# RL6842_IP_SVD register map
Vendor: Realtek
Registers are 32-bit, read-write, reset 0x0 unless marked. A register's access mark holds for its fields unless they carry their own. Offsets are from the block's base; [hi:lo] are bit positions; lines under a group give offsets from that group; {n}, {i} and the like mark numbered series.

## lp_aon
Base 0x4100C000
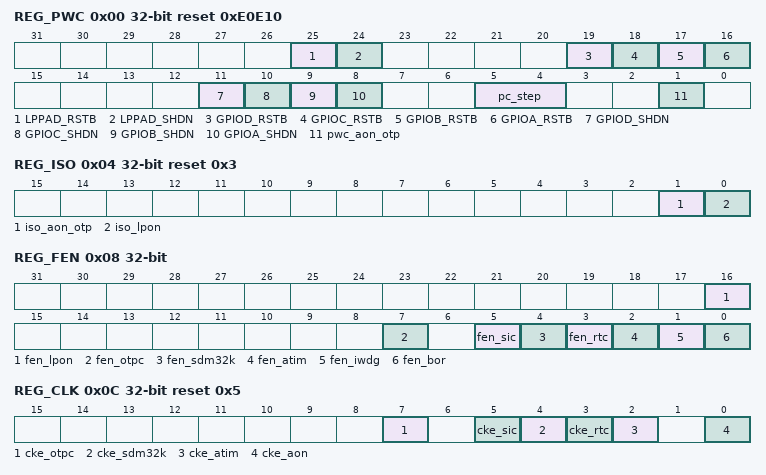
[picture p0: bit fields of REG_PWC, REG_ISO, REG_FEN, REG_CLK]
0x00 REG_PWC reset 0xE0E10
  [25] LPPAD_RSTB — 1: Release LP PAD RSTB33 (except GPIOA) 0: Global Assert LP PAD RSTB33
  [24] LPPAD_SHDN — 1: Global Enable LP PAD (except GPIOA) 0: Shutdown LP PAD Note: Default value must be fixed after AON PMC done.
  [19] GPIOD_RSTB — 1: Enable GPIOD group pad 0: Reset PAD
  [18] GPIOC_RSTB — 1: Enable GPIOC group pad 0: Reset PAD
  [17] GPIOB_RSTB — 1: Enable GPIOB group pad 0: Reset PAD
  [16] GPIOA_RSTB — 1: Enable GPIOA group pad 0: Reset PAD
  [11] GPIOD_SHDN — 1: Enable GPIOD group pad 0: Shutdown PAD
  [10] GPIOC_SHDN — 1: Enable GPIOC group pad 0: Shutdown PAD
  [9] GPIOB_SHDN — 1: Enable GPIOB group pad 0: Shutdown PAD
  [8] GPIOA_SHDN — 1: Enable GPIOA group pad 0: Shutdown PAD
  [5:4] pc_step — power cut enable time step. 0: not valid 1: 10us 2: 20us 3: 30us
  [1] pwc_aon_otp — OTP power cut enable for core power, high active. 1:enable 0:disable
0x04 REG_ISO reset 0x3
  [1] iso_aon_otp — 1: ISO signals from otp core power domain 0: Release
  [0] iso_lpon — When LDO core power on, PD_LPON is on. 1: ISO signal of LPON power domain 0: Release
0x08 REG_FEN
  [16] fen_lpon — LS global reset 1: Enable LS function 0: Disable
  [7] fen_otpc — 1: Enable OTP function 0: Disable
  [5] fen_sic — 1: enable SIC function 0: reset
  [4] fen_sdm32k — 1: Enable 32.768K SDM function 0: Disable
  [3] fen_rtc — 1: Enable RTC function 0: Disable
  [2] fen_atim — 1: Enable AON timer 0: Reset AON timer Note: AON timer starts to run only when event happens.
  [1] fen_iwdg — 1: Enable IWDG by HW autoload. Once enabled, IWDG can't be disabled unless por asserts.
  [0] fen_bor — Enable bor reset function, default is 0 when power on
0x0C REG_CLK reset 0x5
  [7] cke_otpc — 1: Enable OTPC clock 0: Disable
  [5] cke_sic — 1: Enable SIC clock 0: Disable
  [4] cke_sdm32k — 1: Enable 32.768K SDM module's clock 0: Disable
  [3] cke_rtc — 1: Enable RTC clock 0: Disable
  [2] cke_atim — 1: Enable AON timer clock 0: Disable
  [0] cke_aon — if 0, AON clock will be gated except PMC and this register. Note: AON clock can't be shutdown as analog need.
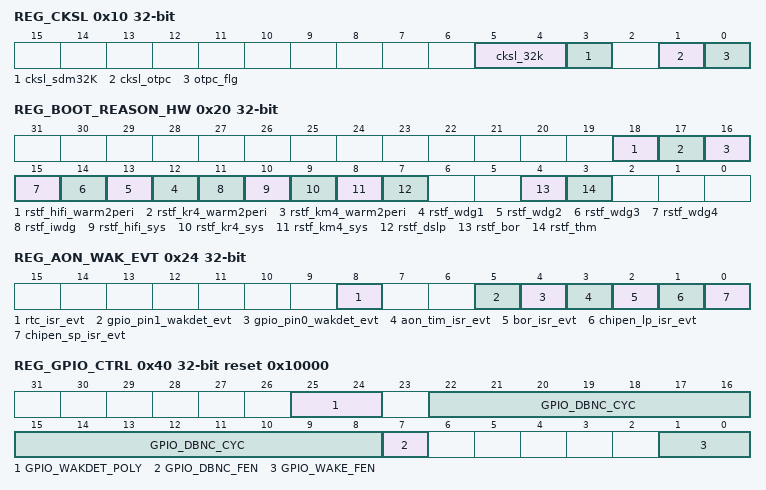
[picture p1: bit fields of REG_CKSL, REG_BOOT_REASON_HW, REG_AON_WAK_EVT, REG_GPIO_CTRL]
0x10 REG_CKSL
  [5:4] cksl_32k — This field is used to select 32K clock. 00/01: SDM32K 10: Crystal 32K 11: External 32K
  [3] cksl_sdm32K — sdm 128 clock select , this must be fixed after initial selection. 0:osc128 1:xtal lps 312.5K
  [1] cksl_otpc — This field is used to select OTPC clk 0: OSC4M 1: XLAL
  [0] otpc_flg — This field is used to indicate OTP autoload field 1: ls 0:aon
0x20 REG_BOOT_REASON_HW ro
  [18] rstf_hifi_warm2peri — This bit will be set to 1 when hifi warm resets the system. Write 1 to clear.
  [17] rstf_kr4_warm2peri — This bit will be set to 1 when kr4 warm resets the system. Write 1 to clear.
  [16] rstf_km4_warm2peri — This bit will be set to 1 when km4 warm resets the system. Write 1 to clear.
  [n+11] rstf_wdg{n} (n=1..4) — This bit will be set to 1 when WDG resets the system. Write 1 to clear.
  [11] rstf_iwdg — This bit will be set to 1 when WDG resets the system. Write 1 to clear.
  [10] rstf_hifi_sys — This bit will be set to 1 when HIFI resets the system. Write 1 to clear.
  [9] rstf_kr4_sys — This bit will be set to 1 when KR4 resets the system. Write 1 to clear.
  [8] rstf_km4_sys — This bit will be set to 1 when KM4 resets the system. Write 1 to clear.
  [7] rstf_dslp — This is boot reason for dslp exit, clear by SW write to 1.
  [4] rstf_bor — This bit will be set to 1 when BOR resets the system. Write 1 to clear.
  [3] rstf_thm — This bit will be set to 1 when THERMAL resets the system. Write 1 to clear.
0x24 REG_AON_WAK_EVT ro
  [8] rtc_isr_evt — RTC interrupt wake event occurs.
  [5] gpio_pin1_wakdet_evt — Wake event for wake pin1 1: wake event detected 0: no wake event Note: aon gpio only used to wake hw pmc, to interrupt SW, it must enable GPIO interrupt in LP GPIO IP, and the poly must be same as AON GPIO setting.
  [4] gpio_pin0_wakdet_evt — Wake event for wake pin0 1: wake event detected 0: no wake event Note: aon gpio only used to wake hw pmc, to interrupt SW, it must enable GPIO interrupt in LP GPIO IP, and the poly must be same as AON GPIO setting.
  [3] aon_tim_isr_evt — AON timer interrupt event occurs.
  [2] bor_isr_evt — bor interrupt event occurs.
  [1] chipen_lp_isr_evt — Chipen long press interrupt event occurs.
  [0] chipen_sp_isr_evt — Chipen short press interrupt event occurs.
0x30 REG_TIM_CNT ro
  [31:0] aon_tim_cnt_cur — Aon timer current count value.
0x34 REG_TIM_SET
  [31:0] aon_tim_cnt_set — Set aon time a countdown value, when timer count down, it will trigger a aon_tim event.
0x38 REG_TIM_IER
  [0] AON_TIM_IE — Timer interrupt enable 0:disable 1:enable
0x3C REG_TIM_ISR ro
  [0] AON_TIM_ISR — Timer interrupt status 0:no interrupt 1:interrupt occurs
0x40 REG_GPIO_CTRL reset 0x10000
  [25:24] GPIO_WAKDET_POLY — Wake pin polarity 0: low active 1: high active bit1: wake pin1 polarity bit0: wake pin0 polarity Note: once a wake pin is set, the pads PU/PD will be force by this poly value, and soft config have no use.
  [22:8] GPIO_DBNC_CYC — The GPIO signal will be filtered by the number of debounce cycles of specified in this register. (100k/128k)
  [7] GPIO_DBNC_FEN — 1: Enable gpio debouncer function 0: Disable Default disable for simualtion issue
  [1:0] GPIO_WAKE_FEN — 1: Enable wake pin function 0: Disable Every GPIO has its own enable. When aon pmc is not in DSLP, wake pins will not effect PMC state althrougth this bit is set.
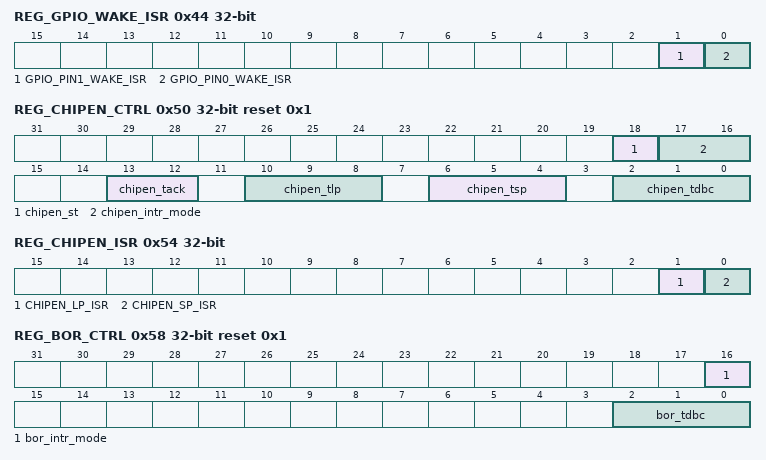
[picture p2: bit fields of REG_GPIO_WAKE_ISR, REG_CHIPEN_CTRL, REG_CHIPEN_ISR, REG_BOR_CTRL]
0x44 REG_GPIO_WAKE_ISR ro
  [1] GPIO_PIN1_WAKE_ISR — Wake pin1 interrupt status 0:no interrupt 1:interrupt occurs
  [0] GPIO_PIN0_WAKE_ISR — Wake pin0 interrupt status 0:no interrupt 1:interrupt occurs
0x50 REG_CHIPEN_CTRL access per field reset 0x1
  [18] chipen_st ro — CHIP_EN pin status 0: logic '0' on CHIP_EN pin 1: logic '1' on CHIP_EN pin
  [17:16] chipen_intr_mode rw — Chipen operation mode. 00: reset mode. When chipen pad low, hw will reset all chip 01: interrup mode. It will enable short/long press function. 1X: pulse reset mode. The transation from other value to 2'd2 will gen a posedge to set RST_PULSE_EN in HV domain. Once in pulse reset mode , this field can't be modified again , and always read out 2'b11
  [13:12] chipen_tack rw — 00: 50ms 01: 100ms 10: 200ms 11: 400ms
  [10:8] chipen_tlp rw — 000: 1000ms 001: 1500ms 010: 2000ms 011: 2500ms 100: 3000ms 101: 3500ms 110: 4000ms 111: 4500ms
  [6:4] chipen_tsp rw — 000: 0ms 001: 50ms 010: 100ms 011: 150ms 100: 200ms 101: 250ms 110: 300ms 111: 350ms
  [2:0] chipen_tdbc rw — 000: 0us 001: 100us 010: 500us 011: 1000us 100: 2000us 101: 4000us 110: 8000us 111: 16000us
0x54 REG_CHIPEN_ISR ro
  [1] CHIPEN_LP_ISR — chipen long press interrupt status 0:no interrupt 1:interrupt occurs
  [0] CHIPEN_SP_ISR — chipen short press interrupt status 0:no interrupt 1:interrupt occurs
0x58 REG_BOR_CTRL reset 0x1
  [16] bor_intr_mode — BOR operation mode. 0: reset mode. When analog detect bor, hw will trigger a bor reset. 1: interrup mode. It will raise an interrup first. If this bit set to 0, then trigger a bor reset.
  [2:0] bor_tdbc — 000: 0us 001: 100us 010: 500us 011: 1000us 100: 2000us 101: 4000us 110: 8000us 111: 16000us
0x5C REG_BOR_ISR ro
  [0] BOR_ISR — BOR interrupt status 0:no interrupt 1:interrupt occurs
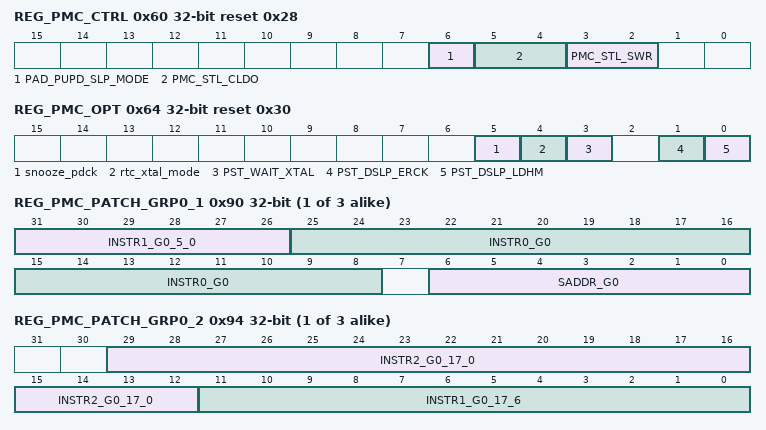
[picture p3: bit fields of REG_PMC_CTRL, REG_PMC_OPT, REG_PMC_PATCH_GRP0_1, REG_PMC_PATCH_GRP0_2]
0x60 REG_PMC_CTRL reset 0x28
  [6] PAD_PUPD_SLP_MODE — Pad pu/pd param selection 1: HW select pu/pd slp param for PAD 0: HW select pu/pd active param for PAD HW will auto-set this bit when enter or exit DSLP , SW can set for debug also .
  [5:4] PMC_STL_CLDO — wait time for core LDO stable 0: 8*T (T = 10us) 1: 16*T 2: 32*T 3: 64*T
  [3:2] PMC_STL_SWR — wait time for SWR stable 0: 64*T (T = 10us) 1: 128*T 2: 256*T 3: 512*T
0x64 REG_PMC_OPT reset 0x30
  [5] snooze_pdck — Select xtal auto pdck function for sdm calibration use xtal lps mode 1:Enable 0:Disable
  [4] rtc_xtal_mode — Select xtal mode when xtal used for sdm calibration. 1: Normal 0: LPS
  [3] PST_WAIT_XTAL — 1: When POF , polling xtal invalid signal and then run forward 0: not polling xtal invalid
  [1] PST_DSLP_ERCK — 1: Enable 100K clock for AON register access when PMC enter deep-sleep mode 0: Disable
  [0] PST_DSLP_LDHM — 0: Enable AON LDO enter into sleep mode when PMC enter deep-sleep mode 1: Disable
0x80 REG_BOOT_CFG
  [0] DSLP_RETENTION_RAM_PATCH — Deepsleep retention RAM patch
0x84 REG_RSVD_FOR_SW1
  [31:0] dummy
{0x90+8i} REG_PMC_PATCH_GRP{i}_1 (i=0..2)
  [31:26] INSTR1_G{i}_5_0 — Instruction1 of AON PMC patch group{i}
  [25:8] INSTR0_G{i} — Instruction0 of AON PMC patch group{i}
  [6:0] SADDR_G{i} — Start address of the first instruction of AON PMC patch group{i}
{0x94+8i} REG_PMC_PATCH_GRP{i}_2 (i=0..2)
  [29:12] INSTR2_G{i}_17_0 — Instruction2 of AON PMC patch group{i}
  [11:0] INSTR1_G{i}_17_6 — Instruction1 of AON PMC patch group{i}
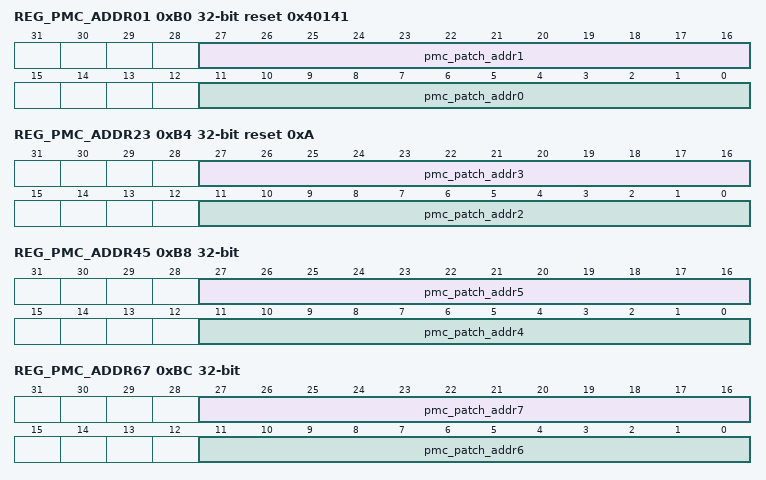
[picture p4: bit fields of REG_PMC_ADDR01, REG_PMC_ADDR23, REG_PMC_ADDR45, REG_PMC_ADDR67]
0xB0 REG_PMC_ADDR01 reset 0x40141
  [27:16] pmc_patch_addr1 — Have used for LPON patch
  [11:0] pmc_patch_addr0 — Have used for LPON patch
0xB4 REG_PMC_ADDR23 reset 0xA
  [27:16] pmc_patch_addr3 — HW used only , these are for pmc patch
  [11:0] pmc_patch_addr2 — Have used for LPON patch
0xB8 REG_PMC_ADDR45
  [27:16] pmc_patch_addr5 — HW used only , these are for pmc patch
  [11:0] pmc_patch_addr4 — HW used only , these are for pmc patch
0xBC REG_PMC_ADDR67
  [27:16] pmc_patch_addr7 — HW used only , these are for pmc patch
  [11:0] pmc_patch_addr6 — HW used only , these are for pmc patch
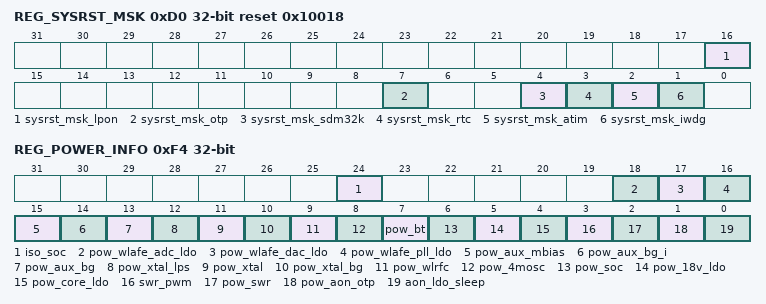
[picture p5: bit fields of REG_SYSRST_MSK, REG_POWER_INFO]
0xD0 REG_SYSRST_MSK reset 0x10018
  [16] sysrst_msk_lpon — LS global reset 1: mask LS reset when sys reset happen 0: reset by sys reset
  [7] sysrst_msk_otp — 1: mask OTP reset when sys reset happen 0: reset by sys reset
  [4] sysrst_msk_sdm32k — 1: mask 32.768K SDM reset when sys reset happen 0: reset by sys reset
  [3] sysrst_msk_rtc — 1: mask RTC reset when sys reset happen 0: reset by sys reset
  [2] sysrst_msk_atim — 1: mask AON timer 0: reset by sys reset OR warm reset Note: AON timer starts to run only when event happens.
  [1] sysrst_msk_iwdg — 1: mask AON IWDG reset 0: reset by sys reset OR warm reset
{0xE0+4i} REG_AON_BACKUP{i} (i=0..3)
  [31:0] dummy
0xF0 REG_BOUNDARY_CHK reset 0xBDC00512
  [31:0] dummy — HW used only . Used for access boundary check, AON is 256B which is 000-FF
0xF4 REG_POWER_INFO ro
  [24] iso_soc — iso control of HSOC power domain
  [18] pow_wlafe_adc_ldo — 1:Power on WLAFE adc ldo 0:Power off WLAFE adc ldo
  [17] pow_wlafe_dac_ldo — 1:Power on WLAFE dac ldo 0:Power off WLAFE dac ldo
  [16] pow_wlafe_pll_ldo — 1:Power on WLAFE power cut and pll ldo 0:Power off WLAFE power cut and pll ldo
  [15] pow_aux_mbias — 1:power on AUX BG mbias 0:power off AUX BG mbias
  [14] pow_aux_bg_i — 1:power on AUX BG current 0:power off AUX BG current
  [13] pow_aux_bg — 1:power on AUX BG 0:power off AUX BG
  [12] pow_xtal_lps — 1: Enable XTAL LPS 0: Disable XTAL LPS
  [11] pow_xtal — 1: Enable XTAL 0: Disable XTAL
  [10] pow_xtal_bg — 1: Enable XTAL Bandgap 0: Disable XTAL Bandgap
  [9] pow_wlrfc — 1: Enable WLRFC power cut 0: Disable WLRFC power cut
  [8] pow_4mosc — 1: Enable OSC4M 0: Disable OSC4M
  [7] pow_bt — 1: Enable BT power cut 0: Disable BT power cut
  [6] pow_soc — 1: Enable HSOC power cut 0: Disable HSOC power cut
  [5] pow_18v_ldo — 0: enable 1.8V LDO 1: disable 1.8V LDO
  [4] pow_core_ldo — 0: enable core LDO 1: disable core LDO
  [3] swr_pwm — 1: SWR PWM mode 0: SWR PFM mode
  [2] pow_swr — 1: enable SWR 0: disable SWR
  [1] pow_aon_otp — 1: Enable AON OTP power cut 0: Disable AON OTP power cut
  [0] aon_ldo_sleep — 1: AON LDO sleep mode 0: AON LDO active mode
0xF8 REG_DUMMY_AIP_CTRL0 reset 0xFFFF
  [31:0] aip_ctrl_rsvd0 — reserved for aip control bit16 is used to turn on/off the path from GPIOC8 to REGU, which is used for vol_config trap, 0 indicate on, 1indicate off
0xFC REG_DUMMY_AIP_INFO0 ro
  [31:0] aip_info_rsvd0 — reserved for aip info indication
